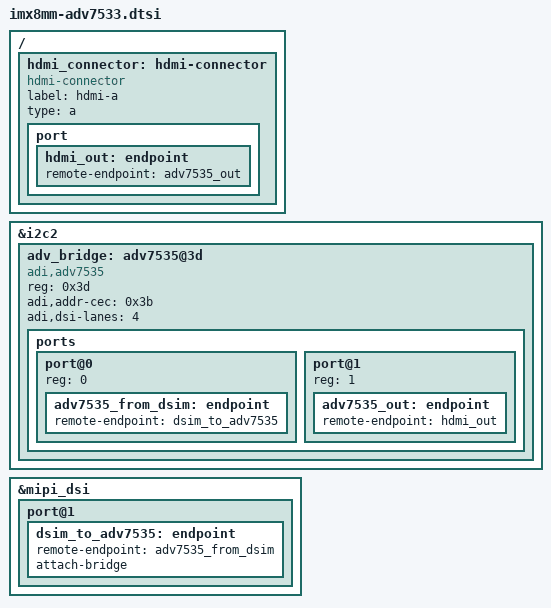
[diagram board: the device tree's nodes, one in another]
/ {
    hdmi_connector: hdmi-connector {
        compatible = "hdmi-connector";
        label = "hdmi-a";
        type = "a";

        port {
            hdmi_out: endpoint {
                remote-endpoint = <&adv7535_out>;
            };
        };
    };
};

&i2c2 {
    status = "okay";

    adv_bridge: adv7535@3d {
        compatible = "adi,adv7535";
        reg = <0x3d>;
        adi,addr-cec = <0x3b>;
        adi,dsi-lanes = <4>;
        status = "okay";

        ports {
            #address-cells = <1>;
            #size-cells = <0>;

            port@0 {
                reg = <0>;
                adv7535_from_dsim: endpoint {
                    remote-endpoint = <&dsim_to_adv7535>;
                };
            };

            port@1 {
                reg = <1>;
                adv7535_out: endpoint {
                    remote-endpoint = <&hdmi_out>;
                };
            };
        };
    };
};

&mipi_dsi {
    status = "okay";

    port@1 {
        dsim_to_adv7535: endpoint {
            remote-endpoint = <&adv7535_from_dsim>;
            attach-bridge;
        };
    };
};

